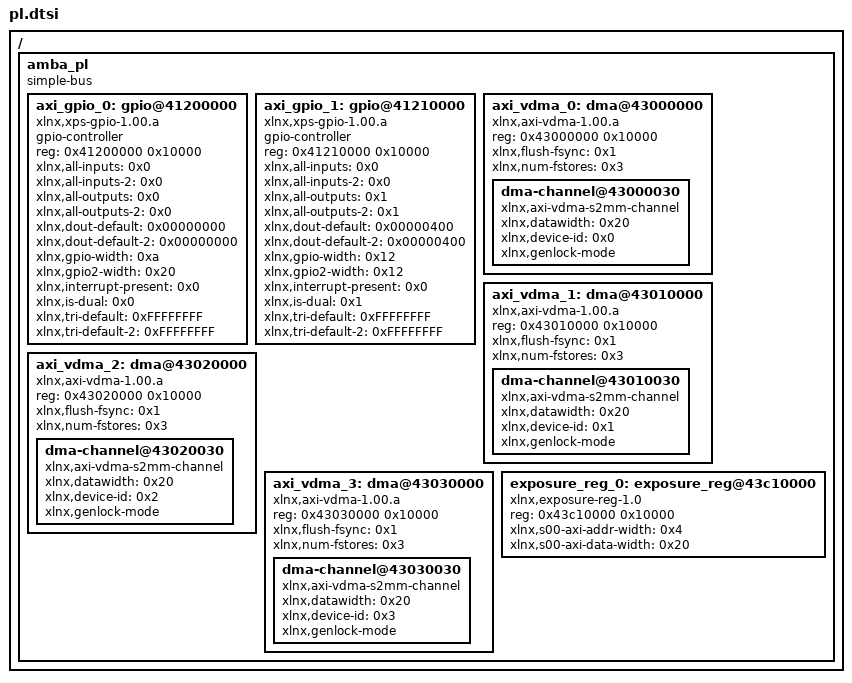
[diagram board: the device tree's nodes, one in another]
/*
 * CAUTION: This file is automatically generated by Xilinx.
 * Version:  
 * Today is: Thu Sep 14 12:08:39 2017
*/


/ {
	amba_pl: amba_pl {
		#address-cells = <1>;
		#size-cells = <1>;
		compatible = "simple-bus";
		ranges ;
		axi_gpio_0: gpio@41200000 {
			#gpio-cells = <2>;
			compatible = "xlnx,xps-gpio-1.00.a";
			gpio-controller ;
			reg = <0x41200000 0x10000>;
			xlnx,all-inputs = <0x0>;
			xlnx,all-inputs-2 = <0x0>;
			xlnx,all-outputs = <0x0>;
			xlnx,all-outputs-2 = <0x0>;
			xlnx,dout-default = <0x00000000>;
			xlnx,dout-default-2 = <0x00000000>;
			xlnx,gpio-width = <0xa>;
			xlnx,gpio2-width = <0x20>;
			xlnx,interrupt-present = <0x0>;
			xlnx,is-dual = <0x0>;
			xlnx,tri-default = <0xFFFFFFFF>;
			xlnx,tri-default-2 = <0xFFFFFFFF>;
		};
		axi_gpio_1: gpio@41210000 {
			#gpio-cells = <2>;
			compatible = "xlnx,xps-gpio-1.00.a";
			gpio-controller ;
			reg = <0x41210000 0x10000>;
			xlnx,all-inputs = <0x0>;
			xlnx,all-inputs-2 = <0x0>;
			xlnx,all-outputs = <0x1>;
			xlnx,all-outputs-2 = <0x1>;
			xlnx,dout-default = <0x00000400>;
			xlnx,dout-default-2 = <0x00000400>;
			xlnx,gpio-width = <0x12>;
			xlnx,gpio2-width = <0x12>;
			xlnx,interrupt-present = <0x0>;
			xlnx,is-dual = <0x1>;
			xlnx,tri-default = <0xFFFFFFFF>;
			xlnx,tri-default-2 = <0xFFFFFFFF>;
		};
		axi_vdma_0: dma@43000000 {
			#dma-cells = <1>;
			compatible = "xlnx,axi-vdma-1.00.a";
			reg = <0x43000000 0x10000>;
			xlnx,flush-fsync = <0x1>;
			xlnx,num-fstores = <0x3>;
			dma-channel@43000030 {
				compatible = "xlnx,axi-vdma-s2mm-channel";
				xlnx,datawidth = <0x20>;
				xlnx,device-id = <0x0>;
				xlnx,genlock-mode ;
			};
		};
		axi_vdma_1: dma@43010000 {
			#dma-cells = <1>;
			compatible = "xlnx,axi-vdma-1.00.a";
			reg = <0x43010000 0x10000>;
			xlnx,flush-fsync = <0x1>;
			xlnx,num-fstores = <0x3>;
			dma-channel@43010030 {
				compatible = "xlnx,axi-vdma-s2mm-channel";
				xlnx,datawidth = <0x20>;
				xlnx,device-id = <0x1>;
				xlnx,genlock-mode ;
			};
		};
		axi_vdma_2: dma@43020000 {
			#dma-cells = <1>;
			compatible = "xlnx,axi-vdma-1.00.a";
			reg = <0x43020000 0x10000>;
			xlnx,flush-fsync = <0x1>;
			xlnx,num-fstores = <0x3>;
			dma-channel@43020030 {
				compatible = "xlnx,axi-vdma-s2mm-channel";
				xlnx,datawidth = <0x20>;
				xlnx,device-id = <0x2>;
				xlnx,genlock-mode ;
			};
		};
		axi_vdma_3: dma@43030000 {
			#dma-cells = <1>;
			compatible = "xlnx,axi-vdma-1.00.a";
			reg = <0x43030000 0x10000>;
			xlnx,flush-fsync = <0x1>;
			xlnx,num-fstores = <0x3>;
			dma-channel@43030030 {
				compatible = "xlnx,axi-vdma-s2mm-channel";
				xlnx,datawidth = <0x20>;
				xlnx,device-id = <0x3>;
				xlnx,genlock-mode ;
			};
		};
		exposure_reg_0: exposure_reg@43c10000 {
			compatible = "xlnx,exposure-reg-1.0";
			reg = <0x43c10000 0x10000>;
			xlnx,s00-axi-addr-width = <0x4>;
			xlnx,s00-axi-data-width = <0x20>;
		};
	};
};
